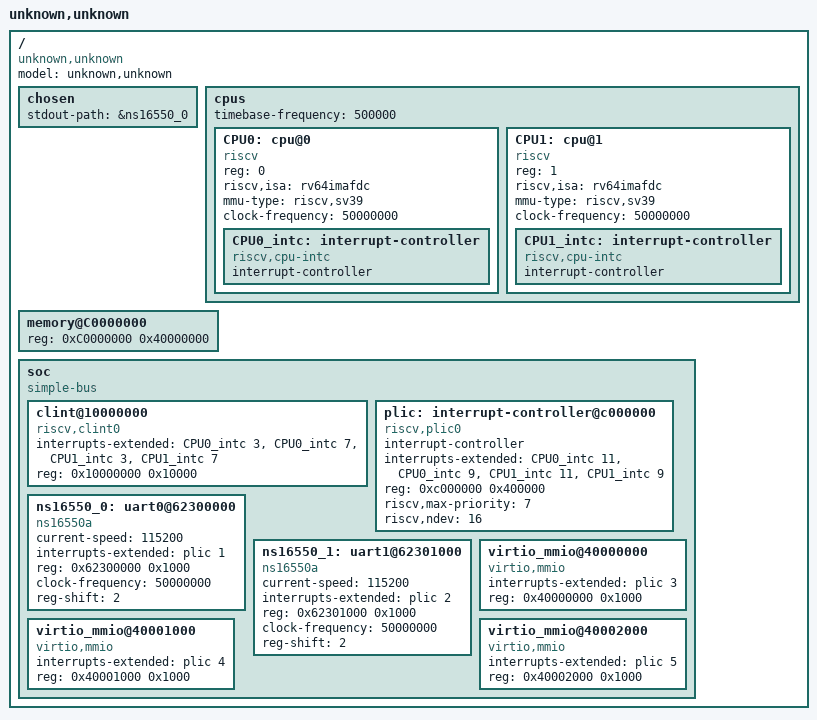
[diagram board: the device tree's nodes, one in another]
/*
 * Copyright (c) 2025, Capabilities Ltd <heshamalmatary@capabilitieslimited.co.uk>
 * This file is copied from the CHERI project.
 * SPDX-License-Identifier: BSD-3-Clause
 */
/dts-v1/;

/ {
    #address-cells = <1>;
    #size-cells = <1>;
    compatible = "unknown,unknown";
    model = "unknown,unknown";
    chosen {
        stdout-path = &ns16550_0;
    };
    cpus {
        #address-cells = <1>;
        #size-cells = <0>;
        timebase-frequency = <500000>;
        CPU0: cpu@0 {
            device_type = "cpu";
            reg = <0>;
            status = "okay";
            compatible = "riscv";
            riscv,isa = "rv64imafdc";
            mmu-type = "riscv,sv39";
            clock-frequency = <50000000>;
            CPU0_intc: interrupt-controller {
                #address-cells = <1>;
		#interrupt-cells = <1>;
                interrupt-controller;
                compatible = "riscv,cpu-intc";
            };
        };
        CPU1: cpu@1 {
		device_type = "cpu";
		reg = <1>;
		status = "okay";
		compatible = "riscv";
		riscv,isa = "rv64imafdc";
		mmu-type = "riscv,sv39";
		clock-frequency = <50000000>;
		CPU1_intc: interrupt-controller {
                        #address-cells = <1>;
			#interrupt-cells = <1>;
			interrupt-controller;
			compatible = "riscv,cpu-intc";
		};
	};
    };
    memory@C0000000 {
        device_type = "memory";
        reg = <0xC0000000 0x40000000>;
    };
    soc {
        #address-cells = <1>;
        #size-cells = <1>;
        compatible = "simple-bus";
        ranges;
        clint@10000000 {
            compatible = "riscv,clint0";
            interrupts-extended = <
                &CPU0_intc 3 &CPU0_intc 7
                &CPU1_intc 3 &CPU1_intc 7
            >;
            reg = <0x10000000 0x10000>;
        };
        plic: interrupt-controller@c000000 {
            #address-cells = <1>;
            #interrupt-cells = <1>;
            compatible = "riscv,plic0";
            interrupt-controller;
            interrupts-extended = <
                &CPU0_intc 11 &CPU0_intc 9
                &CPU1_intc 11 &CPU1_intc 9
            >;
            reg = <0xc000000 0x400000>;
            reg-names = "control";
            riscv,max-priority = <7>;
            riscv,ndev = <16>;
        };
        ns16550_0: uart0@62300000 {
            current-speed = <115200>;
            compatible = "ns16550a";
            interrupts-extended = <&plic 1>;
            reg = <0x62300000 0x1000>;
            clock-frequency = <50000000>;
            reg-shift = <2>;
        };
        ns16550_1: uart1@62301000 {
            current-speed = <115200>;
            compatible = "ns16550a";
            interrupts-extended = <&plic 2>;
            reg = <0x62301000 0x1000>;
            clock-frequency = <50000000>;
            reg-shift = <2>;
        };
        virtio_mmio@40000000 {
            compatible = "virtio,mmio";
            interrupts-extended = <&plic 3>;
            reg = <0x40000000 0x1000>;
        };
        virtio_mmio@40001000 {
            compatible = "virtio,mmio";
            interrupts-extended = <&plic 4>;
            reg = <0x40001000 0x1000>;
        };
        virtio_mmio@40002000 {
            compatible = "virtio,mmio";
            interrupts-extended = <&plic 5>;
            reg = <0x40002000 0x1000>;
        };
    };
};
